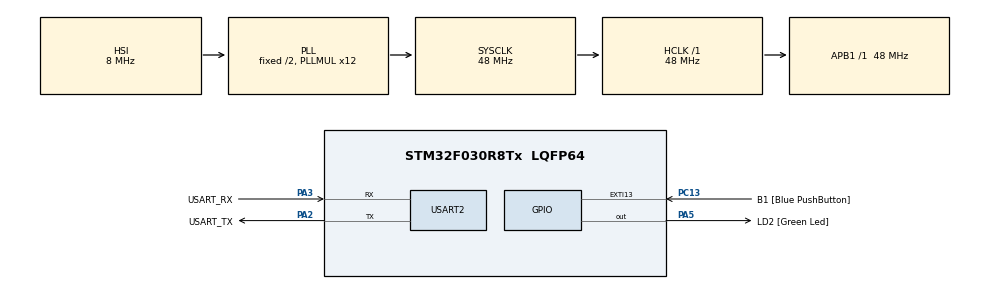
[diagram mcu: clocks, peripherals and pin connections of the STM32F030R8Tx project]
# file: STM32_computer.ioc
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Mcu.Family=STM32F0
PC15-OSC32_OUT.Mode=LSE-External-Oscillator
PA2.GPIO_PuPd=GPIO_NOPULL
PC13.Signal=GPXTI13
PA14.GPIO_Label=TCK
PA3.GPIO_PuPd=GPIO_NOPULL
PA2.GPIO_Speed=GPIO_SPEED_FREQ_LOW
Dma.USART2_RX.0.Direction=DMA_PERIPH_TO_MEMORY
PC13.GPIO_Label=B1 [Blue PushButton]
PC14-OSC32_IN.Signal=RCC_OSC32_IN
PA3.GPIO_Speed=GPIO_SPEED_FREQ_LOW
NVIC.USART2_IRQn=true\:0\:0\:false\:false\:true\:true\:true
RCC.SYSCLKSource=RCC_SYSCLKSOURCE_PLLCLK
ProjectManager.StackSize=0x400
Dma.USART2_RX.0.Mode=DMA_CIRCULAR
PA3.Mode=Asynchronous
PA13.Signal=SYS_SWDIO
ProjectManager.TargetToolchain=STM32CubeIDE
Dma.USART2_RX.0.Priority=DMA_PRIORITY_LOW
PA3.GPIO_Mode=GPIO_MODE_AF_PP
Dma.USART2_RX.0.PeriphDataAlignment=DMA_PDATAALIGN_BYTE
RCC.HCLKFreq_Value=48000000
PC15-OSC32_OUT.Signal=RCC_OSC32_OUT
RCC.AHBFreq_Value=48000000
PF0-OSC_IN.Mode=HSE-External-Clock-Source
PA5.Signal=GPIO_Output
board=NUCLEO-F030R8
USART2.VirtualMode-Asynchronous=VM_ASYNC
RCC.PLLMUL=RCC_PLL_MUL12
NVIC.DMA1_Channel4_5_IRQn=true\:0\:0\:false\:false\:true\:false\:true
Dma.USART2_RX.0.MemDataAlignment=DMA_MDATAALIGN_BYTE
PC14-OSC32_IN.Mode=LSE-External-Oscillator
PA14.Mode=Serial_Wire
PA5.GPIO_PuPd=GPIO_NOPULL
Dma.USART2_RX.0.Instance=DMA1_Channel5
PA13.Mode=Serial_Wire
Mcu.Name=STM32F030R8Tx
Dma.USART2_RX.0.MemInc=DMA_MINC_ENABLE
PA2.Signal=USART2_TX
PA13.GPIO_Label=TMS
RCC.SYSCLKFreq_VALUE=48000000
Mcu.Package=LQFP64
PA5.GPIO_Label=LD2 [Green Led]
Dma.USART2_RX.0.PeriphInc=DMA_PINC_DISABLE
PC13.GPIO_ModeDefaultEXTI=GPIO_MODE_IT_FALLING
PA2.GPIO_Label=USART_TX
PA14.Signal=SYS_SWCLK
ProjectManager.HeapSize=0x200
PA5.GPIO_Speed=GPIO_SPEED_FREQ_LOW
RCC.APB1TimFreq_Value=48000000
PA2.Mode=Asynchronous
PF0-OSC_IN.Signal=RCC_OSC_IN
Dma.Request0=USART2_RX
RCC.APB1Freq_Value=48000000
PA5.GPIO_Mode=GPIO_MODE_OUTPUT_PP
PF1-OSC_OUT.Signal=RCC_OSC_OUT
PA3.GPIO_Label=USART_RX
PA3.Signal=USART2_RX
PA2.GPIO_Mode=GPIO_MODE_AF_PP

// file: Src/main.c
/* USER CODE BEGIN Header */
/**
  ******************************************************************************
  * @file           : main.c
  * @brief          : Main program body
  ******************************************************************************
  * @attention
  *
  * <h2><center>&copy; Copyright (c) 2020 STMicroelectronics.
  * All rights reserved.</center></h2>
  *
  * This software component is licensed by ST under BSD 3-Clause license,
  * the "License"; You may not use this file except in compliance with the
  * License. You may obtain a copy of the License at:
  *                        opensource.org/licenses/BSD-3-Clause
  *
  ******************************************************************************
  */
/* USER CODE END Header */

#include "main.h"
#include "dma.h"
#include "usart.h"
#include "gpio.h"

/* USER CODE BEGIN Includes */
#include "string.h"
/* USER CODE END Includes */

void SystemClock_Config(void);

/* USER CODE BEGIN 0 */
	char data [2];
/* USER CODE END 0 */

int main(void)
{

  /* MCU Configuration--------------------------------------------------------*/

  /* Reset of all peripherals, Initializes the Flash interface and the Systick. */

	HAL_Init();

  /* Configure the system clock */
  SystemClock_Config();

  /* USER CODE BEGIN SysInit */
  	  uint8_t k =0;
  /* USER CODE END SysInit */

  /* Initialize all configured peripherals */
  MX_GPIO_Init();
  MX_DMA_Init();
  MX_USART2_UART_Init();
  /* USER CODE BEGIN 2 */
  HAL_UART_Receive_DMA(&huart2, (uint8_t *)data, 2);
  /* USER CODE END 2 */
  /* Infinite loop */
  while (1)
  {
	  if (k<=1){
	  //HAL_UART_Transmit(&huart2, "la\r\n",6,10);
	  HAL_Delay(100);
	  }
	  k++;
  }
}

void SystemClock_Config(void)
{
  RCC_OscInitTypeDef RCC_OscInitStruct = {0};
  RCC_ClkInitTypeDef RCC_ClkInitStruct = {0};

  /** Initializes the CPU, AHB and APB busses clocks
  */
  RCC_OscInitStruct.OscillatorType = RCC_OSCILLATORTYPE_HSI;
  RCC_OscInitStruct.HSIState = RCC_HSI_ON;
  RCC_OscInitStruct.HSICalibrationValue = RCC_HSICALIBRATION_DEFAULT;
  RCC_OscInitStruct.PLL.PLLState = RCC_PLL_ON;
  RCC_OscInitStruct.PLL.PLLSource = RCC_PLLSOURCE_HSI;
  RCC_OscInitStruct.PLL.PLLMUL = RCC_PLL_MUL12;
  RCC_OscInitStruct.PLL.PREDIV = RCC_PREDIV_DIV1;
  if (HAL_RCC_OscConfig(&RCC_OscInitStruct) != HAL_OK)
  {
    Error_Handler();
  }
  /** Initializes the CPU, AHB and APB busses clocks
  */
  RCC_ClkInitStruct.ClockType = RCC_CLOCKTYPE_HCLK|RCC_CLOCKTYPE_SYSCLK
                              |RCC_CLOCKTYPE_PCLK1;
  RCC_ClkInitStruct.SYSCLKSource = RCC_SYSCLKSOURCE_PLLCLK;
  RCC_ClkInitStruct.AHBCLKDivider = RCC_SYSCLK_DIV1;
  RCC_ClkInitStruct.APB1CLKDivider = RCC_HCLK_DIV1;

  if (HAL_RCC_ClockConfig(&RCC_ClkInitStruct, FLASH_LATENCY_1) != HAL_OK)
  {
    Error_Handler();
  }
}

/* USER CODE BEGIN 4 */

void HAL_UART_RxCpltCallback(UART_HandleTypeDef *huart)
{
  /* Prevent unused argument(s) compilation warning */
  UNUSED(huart);

  /* NOTE : This function should not be modified, when the callback is needed,
            the HAL_UART_RxCpltCallback can be implemented in the user file.
   */
}

/* USER CODE END 4 */

void Error_Handler(void)
{
}

/************************ (C) COPYRIGHT STMicroelectronics *****END OF FILE****/
